# STM32L4R5 register map
File version: 2.4
CPU: CM4 r0p1, little endian, MPU, FPU, 4 interrupt priority bits
Registers are 32-bit, read-write, reset 0x0 unless marked. A register's access mark holds for its fields unless they carry their own. Offsets are from the block's base; [hi:lo] are bit positions.

## FLASH
Base 0x40022000
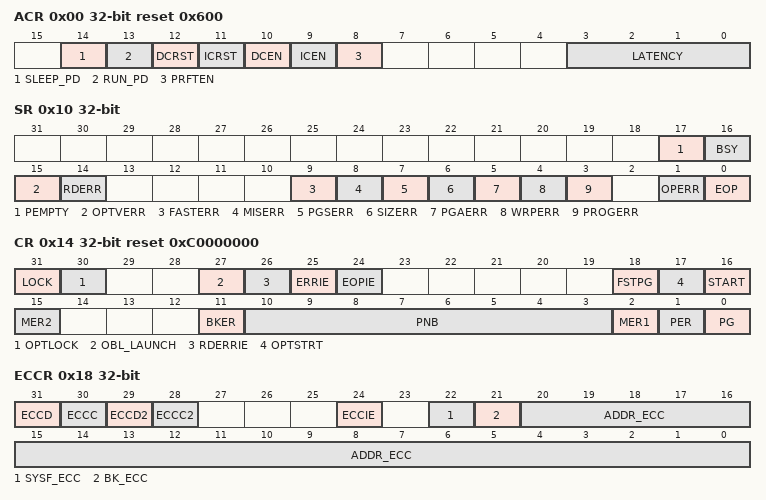
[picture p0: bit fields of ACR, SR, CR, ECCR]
0x00 ACR reset 0x600 — Access control register
  [14] SLEEP_PD — Flash Power-down mode during Low-power sleep mode
  [13] RUN_PD — Flash Power-down mode during Low-power run mode
  [12] DCRST — Data cache reset
  [11] ICRST — Instruction cache reset
  [10] DCEN — Data cache enable
  [9] ICEN — Instruction cache enable
  [8] PRFTEN — Prefetch enable
  [3:0] LATENCY
0x04 PDKEYR wo — Power down key register
  [31:0] PDKEYR — RUN_PD in FLASH_ACR key
0x08 KEYR wo — Flash key register
0x0C OPTKEYR wo — Option byte key register
  [31:0] OPTKEYR — Option byte key
0x10 SR access per field — Status register
  [17] PEMPTY rw — Program EMPTY
  [16] BSY ro — Busy
  [15] OPTVERR rw — Option validity error
  [14] RDERR rw — PCROP read error
  [9] FASTERR rw — Fast programming error
  [8] MISERR rw — Fast programming data miss error
  [7] PGSERR rw — Programming sequence error
  [6] SIZERR rw — Size error
  [5] PGAERR rw — Programming alignment error
  [4] WRPERR rw — Write protected error
  [3] PROGERR rw — Programming error
  [1] OPERR rw — Operation error
  [0] EOP rw — End of operation
0x14 CR reset 0xC0000000 — Flash control register
  [31] LOCK — FLASH_CR Lock
  [30] OPTLOCK — Options Lock
  [27] OBL_LAUNCH — Force the option byte loading
  [26] RDERRIE — PCROP read error interrupt enable
  [25] ERRIE — Error interrupt enable
  [24] EOPIE — End of operation interrupt enable
  [18] FSTPG — Fast programming
  [17] OPTSTRT — Options modification start
  [16] START
  [15] MER2 — Bank 2 Mass erase
  [11] BKER — Bank erase
  [10:3] PNB — Page number
  [2] MER1 — Bank 1 Mass erase
  [1] PER — Page erase
  [0] PG — Programming
0x18 ECCR access per field — Flash ECC register
  [31] ECCD rw — ECC detection
  [30] ECCC rw — ECC correction
  [29] ECCD2 rw — ECC2 detection
  [28] ECCC2 rw — ECC correction
  [24] ECCIE rw — ECC correction interrupt enable
  [22] SYSF_ECC ro — System Flash ECC fail
  [21] BK_ECC ro — ECC fail bank
  [20:0] ADDR_ECC ro — ECC fail address
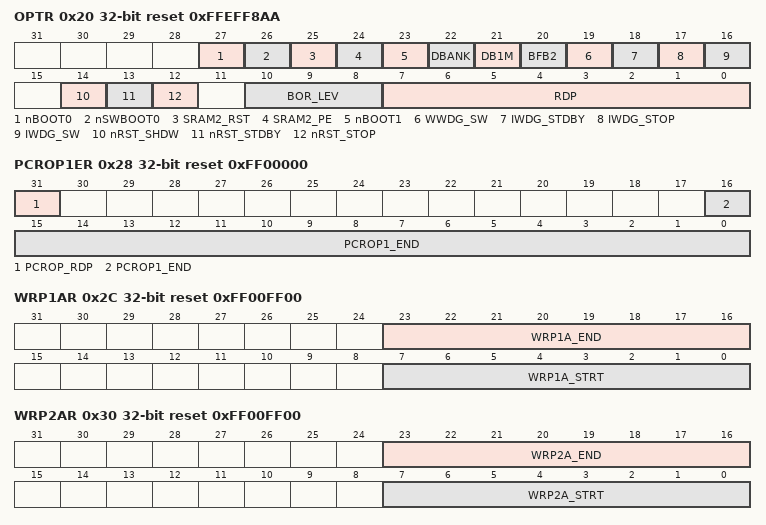
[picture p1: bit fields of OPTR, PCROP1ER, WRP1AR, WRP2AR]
0x20 OPTR reset 0xFFEFF8AA — Flash option register
  [27] nBOOT0 — nBOOT0 option bit
  [26] nSWBOOT0 — Software BOOT0
  [25] SRAM2_RST — SRAM2 Erase when system reset
  [24] SRAM2_PE — SRAM2 parity check enable
  [23] nBOOT1 — Boot configuration
  [22] DBANK
  [21] DB1M — Dual-bank on 1 Mbyte Flash memory devices
  [20] BFB2 — Dual-bank boot
  [19] WWDG_SW — Window watchdog selection
  [18] IWDG_STDBY — Independent watchdog counter freeze in Standby mode
  [17] IWDG_STOP — Independent watchdog counter freeze in Stop mode
  [16] IWDG_SW — Independent watchdog selection
  [14] nRST_SHDW
  [13] nRST_STDBY
  [12] nRST_STOP
  [10:8] BOR_LEV — BOR reset Level
  [7:0] RDP — Read protection level
0x24 PCROP1SR reset 0xFFFFFFFF — Flash Bank 1 PCROP Start address register
  [16:0] PCROP1_STRT — Bank 1 PCROP area start offset
0x28 PCROP1ER reset 0xFF00000 — Flash Bank 1 PCROP End address register
  [31] PCROP_RDP — PCROP area preserved when RDP level decreased
  [16:0] PCROP1_END — Bank 1 PCROP area end offset
0x2C WRP1AR reset 0xFF00FF00 — Flash Bank 1 WRP area A address register
  [23:16] WRP1A_END — Bank 1 WRP first area A end offset
  [7:0] WRP1A_STRT — Bank 1 WRP first area start offset
0x30 WRP2AR reset 0xFF00FF00 — Flash WRP2 area A address register
  [23:16] WRP2A_END — WRP first area A end offset
  [7:0] WRP2A_STRT — WRP first area A start offset
0x44 PCROP2SR reset 0xFFFFFFFF — Flash PCROP2 Start address register
  [16:0] PCROP2_STRT — PCROP area start offset
0x48 PCROP2ER reset 0xFF00000 — Flash PCROP2 End address register
  [16:0] PCROP2_END — Bank 2 PCROP area end offset
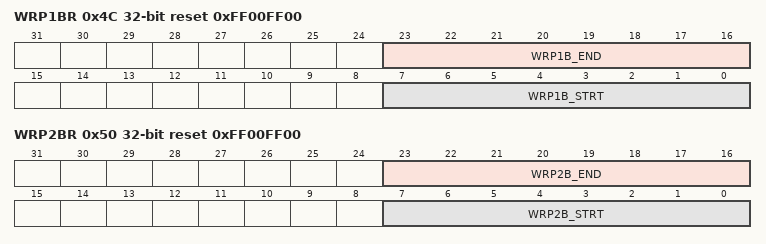
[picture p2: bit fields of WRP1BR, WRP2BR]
0x4C WRP1BR reset 0xFF00FF00 — Flash WRP1 area B address register
  [23:16] WRP1B_END — Bank 2 WRP first area A end offset
  [7:0] WRP1B_STRT — Bank 2 WRP first area A start offset
0x50 WRP2BR reset 0xFF00FF00 — Flash Bank 2 WRP area B address register
  [23:16] WRP2B_END — Bank 2 WRP second area B end offset
  [7:0] WRP2B_STRT — Bank 2 WRP second area B start offset
0x130 CFGR — Flash configuration register
  [0] LVEN — Low voltage enable

## Notices in the file
Copyright (c) 2025 STMicroelectronics.
SPDX-License-Identifier: Apache-2.0
Licensed under the Apache License, Version 2.0 (the "License");
you may not use this file except in compliance with the License.
You may obtain a copy of the License at
http://www.apache.org/licenses/LICENSE-2.0
Unless required by applicable law or agreed to in writing, software
distributed under the License is distributed on an "AS IS" BASIS,
WITHOUT WARRANTIES OR CONDITIONS OF ANY KIND, either express or implied.
See the License for the specific language governing permissions and
limitations under the License.
